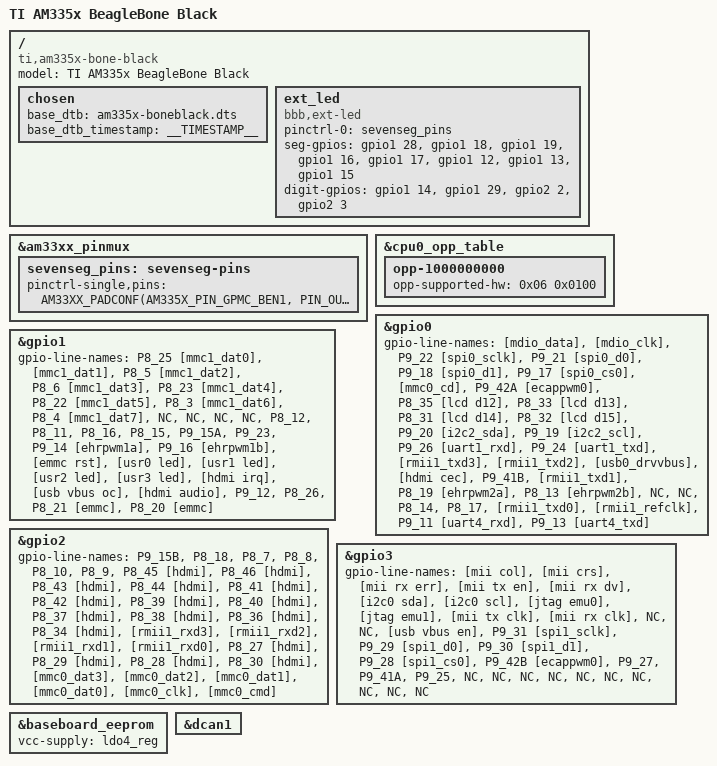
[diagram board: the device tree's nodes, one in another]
// SPDX-License-Identifier: GPL-2.0-only
/*
 * Copyright (C) 2012 Texas Instruments Incorporated - https://www.ti.com/
 */
/dts-v1/;

#include "am33xx.dtsi"
#include "am335x-bone-common.dtsi"
#include "am335x-boneblack-common.dtsi"
#include "am335x-boneblack-hdmi.dtsi"

/ {
	model = "TI AM335x BeagleBone Black";
	compatible = "ti,am335x-bone-black", "ti,am335x-bone", "ti,am33xx";

	chosen {
		base_dtb = "am335x-boneblack.dts";
		base_dtb_timestamp = __TIMESTAMP__;
	};

	/*
	 * 5643AS 4-digit 7-segment display (common cathode, bare module).
	 *
	 * Driven by the bbb_led misc driver (/dev/bbb_led):
	 * write "1" shows "8.8.8.8.", write "0" blanks the display.
	 *
	 * Wiring (see sevenseg_pins below):
	 *   segments a-g,dp : P9_12, P9_14, P9_16, P9_15, P9_23,
	 *                     P8_12, P8_11, P8_15  (220-330 ohm each)
	 *   digits  D1-D4   : P8_16, P8_26, P8_7, P8_8
	 *
	 * A digit common sinks up to 8 segment currents, so each
	 * digit pin must drive the common through an NPN transistor
	 * (or ULN2803). With that transistor, GPIO high selects the
	 * digit, hence GPIO_ACTIVE_HIGH for digit-gpios. If the digit
	 * pins were wired directly to the module (not recommended,
	 * too much current for a GPIO), change them to
	 * GPIO_ACTIVE_LOW instead; the driver needs no change.
	 */
	ext_led {
		compatible = "bbb,ext-led";
		pinctrl-names = "default";
		pinctrl-0 = <&sevenseg_pins>;
		seg-gpios = <&gpio1 28 GPIO_ACTIVE_HIGH>,	/* a  P9_12 */
			    <&gpio1 18 GPIO_ACTIVE_HIGH>,	/* b  P9_14 */
			    <&gpio1 19 GPIO_ACTIVE_HIGH>,	/* c  P9_16 */
			    <&gpio1 16 GPIO_ACTIVE_HIGH>,	/* d  P9_15 */
			    <&gpio1 17 GPIO_ACTIVE_HIGH>,	/* e  P9_23 */
			    <&gpio1 12 GPIO_ACTIVE_HIGH>,	/* f  P8_12 */
			    <&gpio1 13 GPIO_ACTIVE_HIGH>,	/* g  P8_11 */
			    <&gpio1 15 GPIO_ACTIVE_HIGH>;	/* dp P8_15 */
		digit-gpios = <&gpio1 14 GPIO_ACTIVE_HIGH>,	/* D1 P8_16 */
			      <&gpio1 29 GPIO_ACTIVE_HIGH>,	/* D2 P8_26 */
			      <&gpio2 2 GPIO_ACTIVE_HIGH>,	/* D3 P8_7  */
			      <&gpio2 3 GPIO_ACTIVE_HIGH>;	/* D4 P8_8  */
		status = "okay";
	};
};

&am33xx_pinmux {
	sevenseg_pins: sevenseg-pins {
		pinctrl-single,pins = <
			/* segments a-g, dp */
			AM33XX_PADCONF(AM335X_PIN_GPMC_BEN1, PIN_OUTPUT_PULLDOWN, MUX_MODE7)	/* P9_12 gpio1_28 a  */
			AM33XX_PADCONF(AM335X_PIN_GPMC_A2, PIN_OUTPUT_PULLDOWN, MUX_MODE7)	/* P9_14 gpio1_18 b  */
			AM33XX_PADCONF(AM335X_PIN_GPMC_A3, PIN_OUTPUT_PULLDOWN, MUX_MODE7)	/* P9_16 gpio1_19 c  */
			AM33XX_PADCONF(AM335X_PIN_GPMC_A0, PIN_OUTPUT_PULLDOWN, MUX_MODE7)	/* P9_15 gpio1_16 d  */
			AM33XX_PADCONF(AM335X_PIN_GPMC_A1, PIN_OUTPUT_PULLDOWN, MUX_MODE7)	/* P9_23 gpio1_17 e  */
			AM33XX_PADCONF(AM335X_PIN_GPMC_AD12, PIN_OUTPUT_PULLDOWN, MUX_MODE7)	/* P8_12 gpio1_12 f  */
			AM33XX_PADCONF(AM335X_PIN_GPMC_AD13, PIN_OUTPUT_PULLDOWN, MUX_MODE7)	/* P8_11 gpio1_13 g  */
			AM33XX_PADCONF(AM335X_PIN_GPMC_AD15, PIN_OUTPUT_PULLDOWN, MUX_MODE7)	/* P8_15 gpio1_15 dp */
			/* digit commons D1-D4 (via NPN transistors) */
			AM33XX_PADCONF(AM335X_PIN_GPMC_AD14, PIN_OUTPUT_PULLDOWN, MUX_MODE7)	/* P8_16 gpio1_14 D1 */
			AM33XX_PADCONF(AM335X_PIN_GPMC_CSN1, PIN_OUTPUT_PULLDOWN, MUX_MODE7)	/* P8_26 gpio1_29 D2 */
			AM33XX_PADCONF(AM335X_PIN_GPMC_ADVN_ALE, PIN_OUTPUT_PULLDOWN, MUX_MODE7)	/* P8_7  gpio2_2  D3 */
			AM33XX_PADCONF(AM335X_PIN_GPMC_OEN_REN, PIN_OUTPUT_PULLDOWN, MUX_MODE7)	/* P8_8  gpio2_3  D4 */
		>;
	};
};

&cpu0_opp_table {
	/*
	 * All PG 2.0 silicon may not support 1GHz but some of the early
	 * BeagleBone Blacks have PG 2.0 silicon which is guaranteed
	 * to support 1GHz OPP so enable it for PG 2.0 on this board.
	 */
	opp-1000000000 {
		/* OPP Nitro */
		opp-supported-hw = <0x06 0x0100>;
	};
};

&gpio0 {
	gpio-line-names =
		"[mdio_data]",
		"[mdio_clk]",
		"P9_22 [spi0_sclk]",
		"P9_21 [spi0_d0]",
		"P9_18 [spi0_d1]",
		"P9_17 [spi0_cs0]",
		"[mmc0_cd]",
		"P9_42A [ecappwm0]",
		"P8_35 [lcd d12]",
		"P8_33 [lcd d13]",
		"P8_31 [lcd d14]",
		"P8_32 [lcd d15]",
		"P9_20 [i2c2_sda]",
		"P9_19 [i2c2_scl]",
		"P9_26 [uart1_rxd]",
		"P9_24 [uart1_txd]",
		"[rmii1_txd3]",
		"[rmii1_txd2]",
		"[usb0_drvvbus]",
		"[hdmi cec]",
		"P9_41B",
		"[rmii1_txd1]",
		"P8_19 [ehrpwm2a]",
		"P8_13 [ehrpwm2b]",
		"NC",
		"NC",
		"P8_14",
		"P8_17",
		"[rmii1_txd0]",
		"[rmii1_refclk]",
		"P9_11 [uart4_rxd]",
		"P9_13 [uart4_txd]";
};

&gpio1 {
	gpio-line-names =
		"P8_25 [mmc1_dat0]",
		"[mmc1_dat1]",
		"P8_5 [mmc1_dat2]",
		"P8_6 [mmc1_dat3]",
		"P8_23 [mmc1_dat4]",
		"P8_22 [mmc1_dat5]",
		"P8_3 [mmc1_dat6]",
		"P8_4 [mmc1_dat7]",
		"NC",
		"NC",
		"NC",
		"NC",
		"P8_12",
		"P8_11",
		"P8_16",
		"P8_15",
		"P9_15A",
		"P9_23",
		"P9_14 [ehrpwm1a]",
		"P9_16 [ehrpwm1b]",
		"[emmc rst]",
		"[usr0 led]",
		"[usr1 led]",
		"[usr2 led]",
		"[usr3 led]",
		"[hdmi irq]",
		"[usb vbus oc]",
		"[hdmi audio]",
		"P9_12",
		"P8_26",
		"P8_21 [emmc]",
		"P8_20 [emmc]";
};

&gpio2 {
	gpio-line-names =
		"P9_15B",
		"P8_18",
		"P8_7",
		"P8_8",
		"P8_10",
		"P8_9",
		"P8_45 [hdmi]",
		"P8_46 [hdmi]",
		"P8_43 [hdmi]",
		"P8_44 [hdmi]",
		"P8_41 [hdmi]",
		"P8_42 [hdmi]",
		"P8_39 [hdmi]",
		"P8_40 [hdmi]",
		"P8_37 [hdmi]",
		"P8_38 [hdmi]",
		"P8_36 [hdmi]",
		"P8_34 [hdmi]",
		"[rmii1_rxd3]",
		"[rmii1_rxd2]",
		"[rmii1_rxd1]",
		"[rmii1_rxd0]",
		"P8_27 [hdmi]",
		"P8_29 [hdmi]",
		"P8_28 [hdmi]",
		"P8_30 [hdmi]",
		"[mmc0_dat3]",
		"[mmc0_dat2]",
		"[mmc0_dat1]",
		"[mmc0_dat0]",
		"[mmc0_clk]",
		"[mmc0_cmd]";
};

&gpio3 {
	gpio-line-names =
		"[mii col]",
		"[mii crs]",
		"[mii rx err]",
		"[mii tx en]",
		"[mii rx dv]",
		"[i2c0 sda]",
		"[i2c0 scl]",
		"[jtag emu0]",
		"[jtag emu1]",
		"[mii tx clk]",
		"[mii rx clk]",
		"NC",
		"NC",
		"[usb vbus en]",
		"P9_31 [spi1_sclk]",
		"P9_29 [spi1_d0]",
		"P9_30 [spi1_d1]",
		"P9_28 [spi1_cs0]",
		"P9_42B [ecappwm0]",
		"P9_27",
		"P9_41A",
		"P9_25",
		"NC",
		"NC",
		"NC",
		"NC",
		"NC",
		"NC",
		"NC",
		"NC",
		"NC",
		"NC";
};

&baseboard_eeprom {
	vcc-supply = <&ldo4_reg>;
};

&dcan1 {
	status = "okay";
};
